# STM32H7B3 register map
File version: 3.3
CPU: CM7 r0p1, little endian, MPU, FPU, 4 interrupt priority bits
Registers are 32-bit, read-write, reset 0x0 unless marked. A register's access mark holds for its fields unless they carry their own. Offsets are from the block's base; [hi:lo] are bit positions; {n}, {i} and the like mark numbered series; 'fields as' and 'values as' point back to an identical list.

## MDIOS — Management data input/output slave
Base 0x40009400
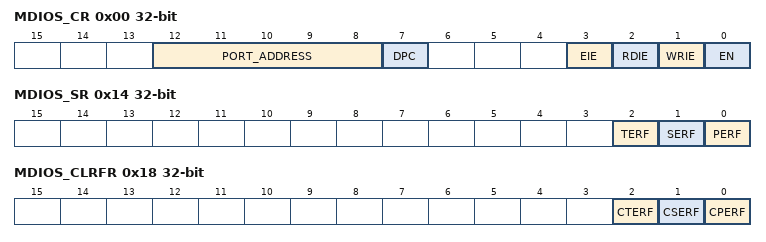
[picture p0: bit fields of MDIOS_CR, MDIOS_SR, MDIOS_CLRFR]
0x00 MDIOS_CR — MDIOS configuration register
  [12:8] PORT_ADDRESS — Slaves's address
  [7] DPC — Disable Preamble Check
  [3] EIE — Error interrupt enable
  [2] RDIE — Register Read Interrupt Enable
  [1] WRIE — Register write interrupt enable
  [0] EN — Peripheral enable
0x04 MDIOS_WRFR ro — MDIOS write flag register
  [31:0] WRF — Write flags for MDIO registers 0 to 31
0x08 MDIOS_CWRFR — MDIOS clear write flag register
  [31:0] CWRF — Clear the write flag
0x0C MDIOS_RDFR ro — MDIOS read flag register
  [31:0] RDF — Read flags for MDIO registers 0 to 31
0x10 MDIOS_CRDFR — MDIOS clear read flag register
  [31:0] CRDF — Clear the read flag
0x14 MDIOS_SR ro — MDIOS status register
  [2] TERF — Turnaround error flag
  [1] SERF — Start error flag
  [0] PERF — Preamble error flag
0x18 MDIOS_CLRFR — MDIOS clear flag register
  [2] CTERF — Clear the turnaround error flag
  [1] CSERF — Clear the start error flag
  [0] CPERF — Clear the preamble error flag
{0x1C+4i} MDIOS_DINR{i} ro (i=0..31) — MDIOS input data register {i}
  [15:0] DIN{i} — Input data received from MDIO Master during write frames
{0x9C+4i} MDIOS_DOUTR{i} (i=0..31) — MDIOS output data register {i}
  [15:0] DOUT{i} — Output data sent to MDIO Master during read frames

## OPAMP — Operational amplifiers
Base 0x40009000
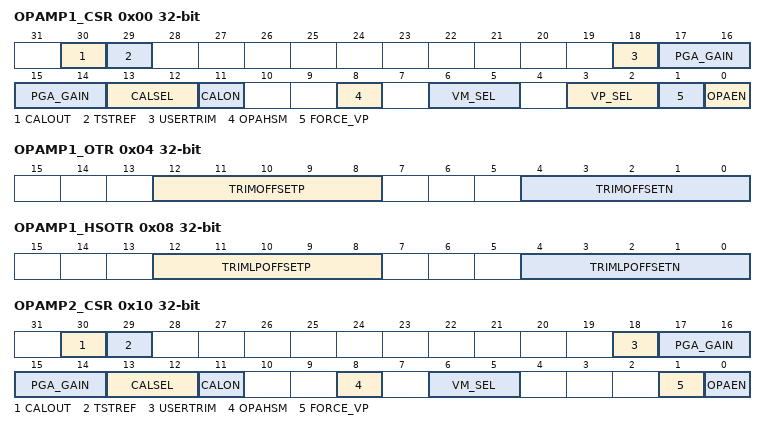
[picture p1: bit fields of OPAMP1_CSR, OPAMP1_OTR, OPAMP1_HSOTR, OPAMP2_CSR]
0x00 OPAMP1_CSR — OPAMP1 control/status register
  [30] CALOUT — Operational amplifier calibration output
  [29] TSTREF — OPAMP calibration reference voltage output control (reserved for test)
  [18] USERTRIM — User trimming enable
  [17:14] PGA_GAIN — allows to switch from AOP offset trimmed values to AOP offset
  [13:12] CALSEL — Calibration selection
  [11] CALON — Calibration mode enabled
  [8] OPAHSM — Operational amplifier high-speed mode
  [6:5] VM_SEL — Inverting input selection
  [3:2] VP_SEL — Operational amplifier PGA mode
  [1] FORCE_VP — Force internal reference on VP (reserved for test
  [0] OPAEN — Operational amplifier Enable
0x04 OPAMP1_OTR — OPAMP1 offset trimming register in normal mode
  [12:8] TRIMOFFSETP — Trim for PMOS differential pairs
  [4:0] TRIMOFFSETN — Trim for NMOS differential pairs
0x08 OPAMP1_HSOTR — OPAMP1 offset trimming register in low-power mode
  [12:8] TRIMLPOFFSETP — Trim for PMOS differential pairs
  [4:0] TRIMLPOFFSETN — Trim for NMOS differential pairs
0x10 OPAMP2_CSR — OPAMP2 control/status register
  [30] CALOUT — Operational amplifier calibration output
  [29] TSTREF — OPAMP calibration reference voltage output control (reserved for test)
  [18] USERTRIM — User trimming enable
  [17:14] PGA_GAIN — Operational amplifier Programmable amplifier gain value
  [13:12] CALSEL — Calibration selection
  [11] CALON — Calibration mode enabled
  [8] OPAHSM — Operational amplifier high-speed mode
  [6:5] VM_SEL — Inverting input selection
  [1] FORCE_VP — Force internal reference on VP (reserved for test)
  [0] OPAEN — Operational amplifier Enable
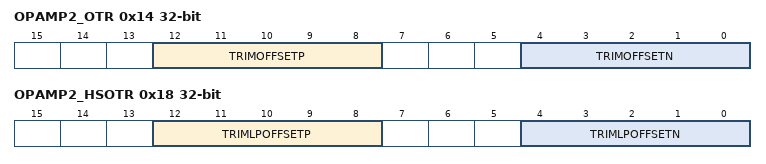
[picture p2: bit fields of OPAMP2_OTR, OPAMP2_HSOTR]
0x14 OPAMP2_OTR — OPAMP2 offset trimming register in normal mode
  fields as OPAMP1_OTR
0x18 OPAMP2_HSOTR — OPAMP2 offset trimming register in low-power mode
  fields as OPAMP1_HSOTR

## OTFDEC1 — On-The-Fly Decryption engine
Base 0x5200B800
Same registers: OTFDEC2 0x5200BC00
0x00 CR — OTFDEC control register
  [0] ENC — Encryption mode bit
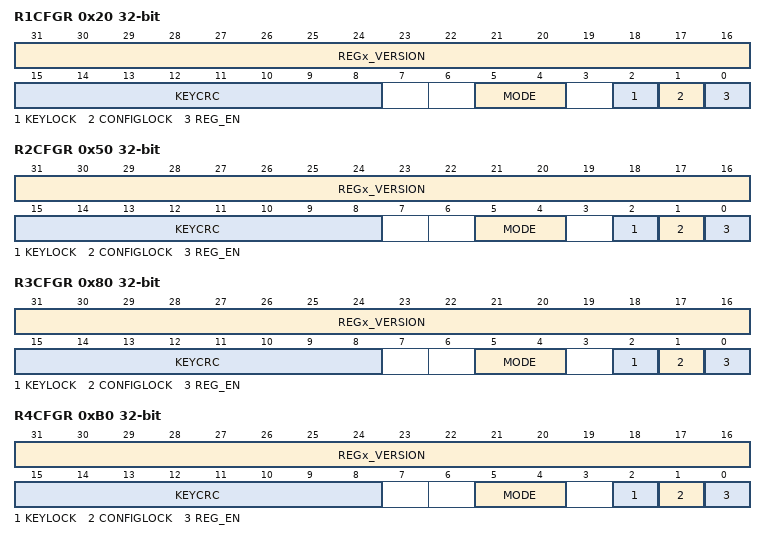
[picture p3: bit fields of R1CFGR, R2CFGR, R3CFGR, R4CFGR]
0x20 R1CFGR access per field — OTFDEC region x configuration register
  [31:16] REGx_VERSION rw — region firmware version
  [15:8] KEYCRC ro — region key 8-bit CRC
  [5:4] MODE rw — operating mode
  [2] KEYLOCK rw — region key lock
  [1] CONFIGLOCK rw — region config lock
  [0] REG_EN rw — region on-the-fly decryption enable
0x24 R1STARTADDR — OTFDEC region x start address register
  [31:0] REGx_START_ADDR — Region AXI start address
0x28 R1ENDADDR reset 0xFFF — OTFDEC region x end address register
  [31:0] REGx_END_ADDR — Region AXI end address
0x2C R1NONCER0 — OTFDEC region x nonce register 0
  [31:0] REGx_NONCE
0x30 R1NONCER1 — OTFDEC region x nonce register 1
  [31:0] REGx_NONCE — Region nonce
{0x4+0x30*i} R{i}KEYR0 wo (i=1..4) — OTFDEC region x key register 0
  [31:0] REGx_KEY
{0x8+0x30*i} R{i}KEYR1 wo (i=1..4) — OTFDEC region x key register 1
  [31:0] REGx_KEY
0x3C R1KEYR2 wo — OTFDEC region x key register 2
  [31:0] REGx_KEY
{0x10+0x30*i} R{i}KEYR3 wo (i=1..4) — OTFDEC region x key register 3
  [31:0] REGx_KEY
0x50 R2CFGR access per field — OTFDEC region x configuration register
  fields as R1CFGR
0x54 R2STARTADDR — OTFDEC region x start address register
  [31:0] REGx_START_ADDR — Region AXI start address
0x58 R2ENDADDR reset 0xFFF — OTFDEC region x end address register
  [31:0] REGx_END_ADDR — Region AXI end address
0x5C R2NONCER0 — OTFDEC region x nonce register 0
  [31:0] REGx_NONCE
0x60 R2NONCER1 — OTFDEC region x nonce register 1
  [31:0] REGx_NONCE — Region nonce, bits [63:32]REGx_NONCE[63:32]
0x6C R2KEYR2 wo — OTFDEC region x key register 2
  [31:0] REGx_KEY_
0x80 R3CFGR access per field — OTFDEC region x configuration register
  fields as R1CFGR
0x84 R3STARTADDR — OTFDEC region x start address register
  [31:0] REGx_START_ADDR — Region AXI start address
0x88 R3ENDADDR reset 0xFFF — OTFDEC region x end address register
  [31:0] REGx_END_ADDR — Region AXI end address
0x8C R4ENDADDR reset 0xFFF — OTFDEC region x end address register
  [31:0] REGx_END_ADDR — Region AXI end address
0x8C R3NONCER0 (alternate view of R4ENDADDR) — OTFDEC region x nonce register 0
  [31:0] REGx_NONCE
0x90 R3NONCER1 — OTFDEC region x nonce register 1
  [31:0] REGx_NONCE
0x9C R3KEYR2 wo — OTFDEC region x key register 2
  [31:0] REGx_KEY
0xB0 R4CFGR access per field — OTFDEC region x configuration register
  fields as R1CFGR
0xB4 R4STARTADDR — OTFDEC region x start address register
  [31:0] REGx_START_ADDR — Region AXI start address
0xBC R4NONCER0 — OTFDEC region x nonce register 0
  [31:0] REGx_NONCE
0xC0 R4NONCER1 — OTFDEC region x nonce register 1
  [31:0] REGx_NONCE
0xCC R4KEYR2 wo — OTFDEC region x key register 2
  [31:0] REGx_KEY
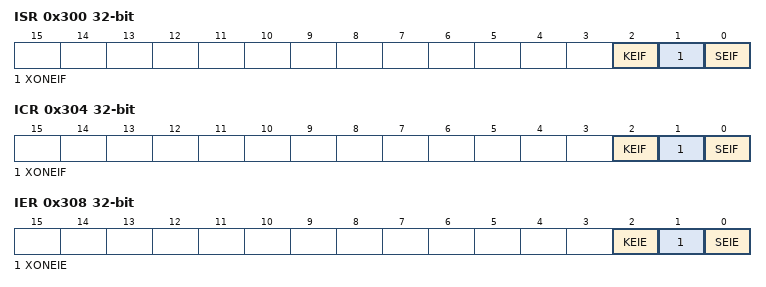
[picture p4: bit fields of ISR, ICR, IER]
0x300 ISR ro — OTFDEC interrupt status register
  [2] KEIF — Key Error Interrupt Flag status
  [1] XONEIF — Execute-only execute-Never Error Interrupt Flag status
  [0] SEIF — Security Error Interrupt Flag status
0x304 ICR ro — OTFDEC interrupt clear register
  [2] KEIF
  [1] XONEIF — Execute-only execute-Never Error Interrupt Flag clear
  [0] SEIF
0x308 IER — OTFDEC interrupt enable register
  [2] KEIE
  [1] XONEIE
  [0] SEIE — Security Error Interrupt Enable
